# APM32M35XX register map
File version: 1.0
Registers are 32-bit, read-write, reset 0x0 unless marked. A register's access mark holds for its fields unless they carry their own. Offsets are from the block's base; [hi:lo] are bit positions; {n}, {i} and the like mark numbered series.

## TMR1 — Advanced-timers
Base 0x40012C00
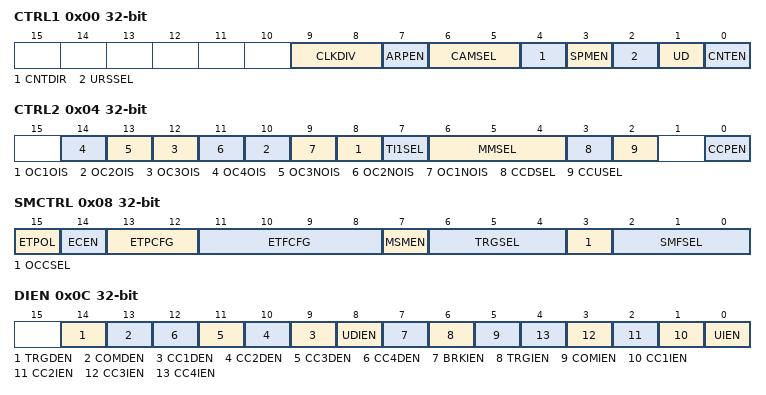
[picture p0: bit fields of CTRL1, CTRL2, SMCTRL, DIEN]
0x00 CTRL1 — control register 1
  [9:8] CLKDIV — Clock division
  [7] ARPEN — Auto-reload preload enable
  [6:5] CAMSEL — Center-aligned mode selection
  [4] CNTDIR — Direction
  [3] SPMEN — One-pulse mode
  [2] URSSEL — Update request source
  [1] UD — Update disable
  [0] CNTEN — Counter enable
0x04 CTRL2 — control register 2
  [2n+6] OC{n}OIS (n=1..4) — Output Idle state {n}
  [13] OC3NOIS — Output Idle state 3
  [11] OC2NOIS — Output Idle state 2
  [9] OC1NOIS — Output Idle state 1
  [7] TI1SEL — TI1 selection
  [6:4] MMSEL — Master mode selection
  [3] CCDSEL — Capture/compare DMA selection
  [2] CCUSEL — Capture/compare control update selection
  [0] CCPEN — Capture/compare preloaded control
0x08 SMCTRL — slave mode control register
  [15] ETPOL — External trigger polarity
  [14] ECEN — External clock enable
  [13:12] ETPCFG — External trigger prescaler
  [11:8] ETFCFG — External trigger filter
  [7] MSMEN — Master/Slave mode
  [6:4] TRGSEL — Trigger selection
  [3] OCCSEL — OCREF clear selection
  [2:0] SMFSEL — Slave mode selection
0x0C DIEN — DMA/Interrupt enable register
  [14] TRGDEN — Trigger DMA request enable
  [13] COMDEN — Reserved
  [n+8] CC{n}DEN (n=1..4) — Capture/Compare {n} DMA request enable
  [8] UDIEN — Update DMA request enable
  [7] BRKIEN — Break interrupt enable
  [6] TRGIEN — Trigger interrupt enable
  [5] COMIEN — COM interrupt enable
  [n] CC{n}IEN (n=1..4) — Capture/Compare {n} interrupt enable
  [0] UIEN — Update interrupt enable
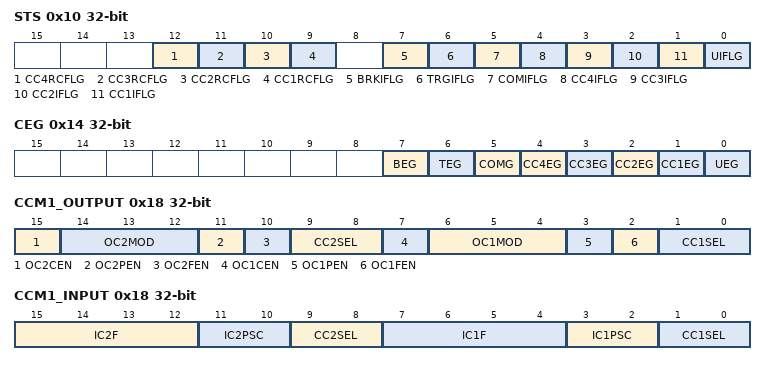
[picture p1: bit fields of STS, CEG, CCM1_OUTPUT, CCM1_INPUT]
0x10 STS — status register
  [12] CC4RCFLG — Capture/Compare 4 overcapture flag
  [11] CC3RCFLG — Capture/Compare 3 overcapture flag
  [10] CC2RCFLG — Capture/compare 2 overcapture flag
  [9] CC1RCFLG — Capture/Compare 1 overcapture flag
  [7] BRKIFLG — Break interrupt flag
  [6] TRGIFLG — Trigger interrupt flag
  [5] COMIFLG — COM interrupt flag
  [4] CC4IFLG — Capture/Compare 4 interrupt flag
  [3] CC3IFLG — Capture/Compare 3 interrupt flag
  [2] CC2IFLG — Capture/Compare 2 interrupt flag
  [1] CC1IFLG — Capture/compare 1 interrupt flag
  [0] UIFLG — Update interrupt flag
0x14 CEG wo — event generation register
  [7] BEG — Break generation
  [6] TEG — Trigger generation
  [5] COMG — Capture/Compare control update generation
  [n] CC{n}EG (n=1..4) — Capture/compare {n} generation
  [0] UEG — Update generation
0x18 CCM1_OUTPUT — capture/compare mode register (output mode)
  [15] OC2CEN — Output Compare 2 clear enable
  [14:12] OC2MOD — Output Compare 2 mode
  [11] OC2PEN — Output Compare 2 preload enable
  [10] OC2FEN — Output Compare 2 fast enable
  [9:8] CC2SEL — Capture/Compare 2 selection
  [7] OC1CEN — Output Compare 1 clear enable
  [6:4] OC1MOD — Output Compare 1 mode
  [3] OC1PEN — Output Compare 1 preload enable
  [2] OC1FEN — Output Compare 1 fast enable
  [1:0] CC1SEL — Capture/Compare 1 selection
0x18 CCM1_INPUT (alternate view of CCM1_OUTPUT) — capture/compare mode register 1 (input mode)
  [15:12] IC2F — Input capture 2 filter
  [11:10] IC2PSC — Input capture 2 prescaler
  [9:8] CC2SEL — Capture/Compare 2 selection
  [7:4] IC1F — Input capture 1 filter
  [3:2] IC1PSC — Input capture 1 prescaler
  [1:0] CC1SEL — Capture/Compare 1 selection
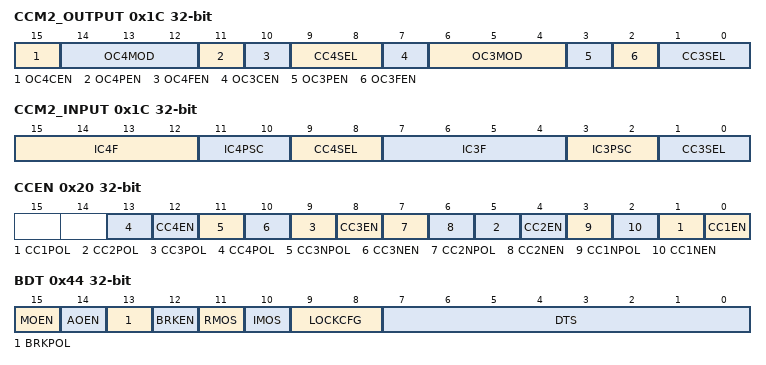
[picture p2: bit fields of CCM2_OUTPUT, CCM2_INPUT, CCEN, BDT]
0x1C CCM2_OUTPUT — capture/compare mode register (output mode)
  [15] OC4CEN — Output compare 4 clear enable
  [14:12] OC4MOD — Output compare 4 mode
  [11] OC4PEN — Output compare 4 preload enable
  [10] OC4FEN — Output compare 4 fast enable
  [9:8] CC4SEL — Capture/Compare 4 selection
  [7] OC3CEN — Output compare 3 clear enable
  [6:4] OC3MOD — Output compare 3 mode
  [3] OC3PEN — Output compare 3 preload enable
  [2] OC3FEN — Output compare 3 fast enable
  [1:0] CC3SEL — Capture/Compare 3 selection
0x1C CCM2_INPUT (alternate view of CCM2_OUTPUT) — capture/compare mode register 2 (input mode)
  [15:12] IC4F — Input capture 4 filter
  [11:10] IC4PSC — Input capture 4 prescaler
  [9:8] CC4SEL — Capture/Compare 4 selection
  [7:4] IC3F — Input capture 3 filter
  [3:2] IC3PSC — Input capture 3 prescaler
  [1:0] CC3SEL — Capture/compare 3 selection
0x20 CCEN — capture/compare enable register
  [4n-3] CC{n}POL (n=1..4) — Capture/Compare {n} output Polarity
  [4n-4] CC{n}EN (n=1..4) — Capture/Compare {n} output enable
  [11] CC3NPOL — Capture/Compare 3 output Polarity
  [10] CC3NEN — Capture/Compare 3 complementary output enable
  [7] CC2NPOL — Capture/Compare 2 output Polarity
  [6] CC2NEN — Capture/Compare 2 complementary output enable
  [3] CC1NPOL — Capture/Compare 1 output Polarity
  [2] CC1NEN — Capture/Compare 1 complementary output enable
0x24 CNT — counter
  [15:0] CNT — counter value
0x28 PSC — prescaler
  [15:0] PSC — Prescaler value
0x2C AUTORLD reset 0xFFFF — auto-reload register
  [15:0] AUTORLD — Auto-reload value
0x30 REPCNT — repetition counter register
  [7:0] REPCNT — Repetition counter value
{0x30+4i} CC{i} (i=1..3) — capture/compare register {i}
  [15:0] CC{i} — Capture/Compare {i} value
0x40 CC4 — capture/compare register 4
  [15:0] CC4 — Capture/Compare 3 value
0x44 BDT — break and dead-time register
  [15] MOEN — Main output enable
  [14] AOEN — Automatic output enable
  [13] BRKPOL — Break polarity
  [12] BRKEN — Break enable
  [11] RMOS — Off-state selection for Run mode
  [10] IMOS — Off-state selection for Idle mode
  [9:8] LOCKCFG — Lock configuration
  [7:0] DTS — Dead-time generator setup
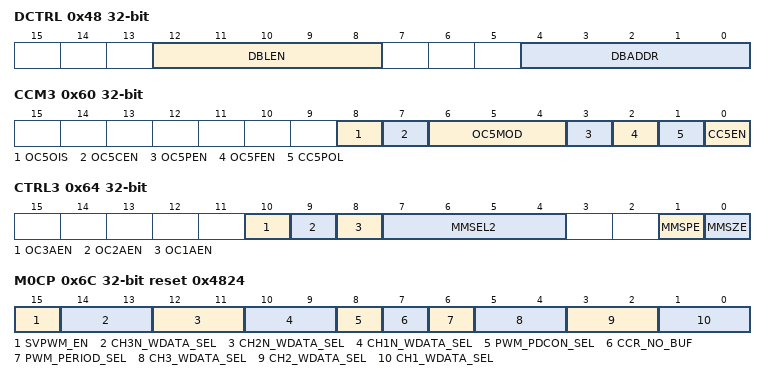
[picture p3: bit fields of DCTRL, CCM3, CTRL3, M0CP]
0x48 DCTRL — DMA control register
  [12:8] DBLEN — DMA burst length
  [4:0] DBADDR — DMA base address
0x4C DMADDR — DMA address for full transfer
  [15:0] DMADDR — DMA register for burst accesses
{0x4C+4i} CC{i}C (i=1..3) — capture/compare register complementary register {i}
  [15:0] CC{i}C — Channel {i} capture/compare register complementary register
0x5C CC5 — capture/compare register 5
  [15:0] CC5 — Capture/compare channel 5 value
0x60 CCM3 — capture/compare mode register (output mode)
  [8] OC5OIS — OC5 output idel state configure
  [7] OC5CEN — Output compare 5 clear enable
  [6:4] OC5MOD — Output compare 5 mode configure
  [3] OC5PEN — Output compare 5 preload enable
  [2] OC5FEN — Output compare 5 fast enable
  [1] CC5POL — Output compare 5 output polarity configure
  [0] CC5EN — Output compare 5 enable
0x64 CTRL3 — control register 3
  [10] OC3AEN — Output compare 3 asynchronous mode configure
  [9] OC2AEN — Output compare 2 asynchronous mode configure
  [8] OC1AEN — Output compare 1 asynchronous mode configure
  [7:4] MMSEL2 — Master mode signal select
  [1] MMSPE — TRGO when counter matches the autoreload register
  [0] MMSZE — TRGO when the counter returns to 0
0x68 BKFT — brake filter register
  [3:0] BKF — External brake input filter
0x6C M0CP reset 0x4824
  [15] SVPWM_EN — SVPWM function enable
  [14:13] CH3N_WDATA_SEL — Channel 3N data selection
  [12:11] CH2N_WDATA_SEL — Channel 2N data selection
  [10:9] CH1N_WDATA_SEL — Channel 1N data selection
  [8] PWM_PDCON_SEL — PDCON select
  [7] CCR_NO_BUF — CCR buffer enable
  [6] PWM_PERIOD_SEL — PWM cycle selection
  [5:4] CH3_WDATA_SEL — Channel 3 data selection
  [3:2] CH2_WDATA_SEL — Channel 2 data selection
  [1:0] CH1_WDATA_SEL — Channel 1 data selection
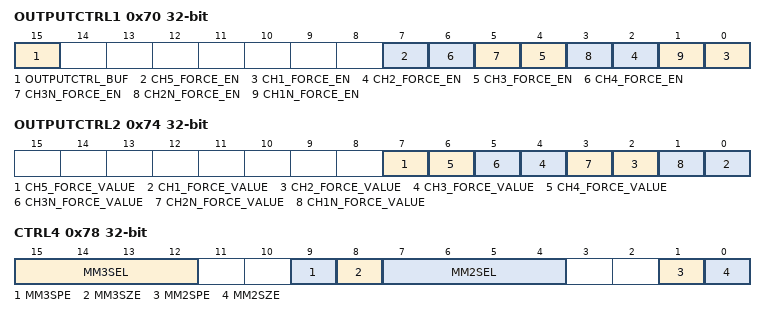
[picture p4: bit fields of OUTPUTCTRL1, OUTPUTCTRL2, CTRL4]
0x70 OUTPUTCTRL1 — output control register 1
  [15] OUTPUTCTRL_BUF — Output control buffering enable
  [7] CH5_FORCE_EN — Channel 5 outputs the control enable
  [2n-2] CH{n}_FORCE_EN (n=1..4) — Channel {n} outputs the control enable
  [5] CH3N_FORCE_EN — Complementary channel outputs the control enable for channel 3
  [3] CH2N_FORCE_EN — Complementary channel outputs the control enable for channel 2
  [1] CH1N_FORCE_EN — Complementary channel outputs the control enable for channel 1
0x74 OUTPUTCTRL2 — output control register 2
  [7] CH5_FORCE_VALUE — Channel 5 output level
  [2n-2] CH{n}_FORCE_VALUE (n=1..4) — Channel {n} output level
  [5] CH3N_FORCE_VALUE — Complementary channel output level for channel 3
  [3] CH2N_FORCE_VALUE — Complementary channel output level for channel 2
  [1] CH1N_FORCE_VALUE — Complementary channel output level for channel 1
0x78 CTRL4 — control register 4
  [15:12] MM3SEL — Master mode signal select
  [9] MM3SPE — TRGO3 when counter matches the autoreload register
  [8] MM3SZE — TRGO3 when the counter returns to 0
  [7:4] MM2SEL — Master mode signal select
  [1] MM2SPE — TRGO2 when counter matches the autoreload register
  [0] MM2SZE — TRGO2 when the counter returns to 0

## TMR2 — General-purpose-timers
Base 0x40000000
Same registers: TMR3 0x40000400, TMR4 0x40002000
Registers as TMR1, without REPCNT, BDT, CC{n}C (n=1..3), CC5, CCM3, CTRL3, BKFT, M0CP, OUTPUTCTRL1, OUTPUTCTRL2, CTRL4; these are added or differ:
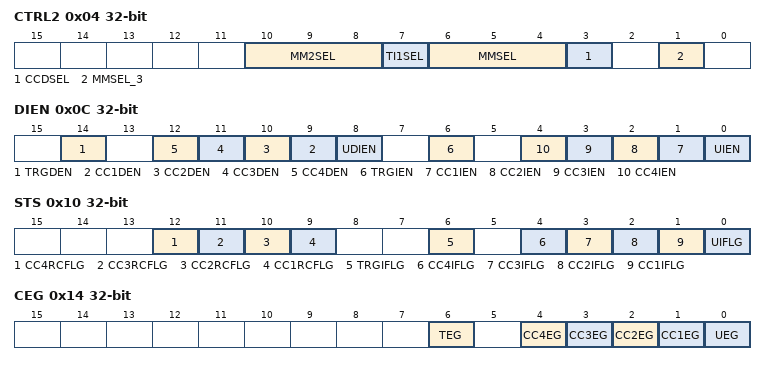
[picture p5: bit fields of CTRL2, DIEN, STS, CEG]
0x04 CTRL2 — control register 2
  [10:8] MM2SEL — Master Mode 2 Signal Select
  [7] TI1SEL — TI1 selection
  [6:4] MMSEL — Master mode selection
  [3] CCDSEL — Capture/compare DMA selection
  [1] MMSEL_3 — Supplementary signal of MMSEL
0x0C DIEN — DMA/Interrupt enable register
  [14] TRGDEN — Trigger DMA request enable
  [n+8] CC{n}DEN (n=1..4) — Capture/Compare {n} DMA request enable
  [8] UDIEN — Update DMA request enable
  [6] TRGIEN — Trigger interrupt enable
  [n] CC{n}IEN (n=1..4) — Capture/Compare {n} interrupt enable
  [0] UIEN — Update interrupt enable
0x10 STS — status register
  [12] CC4RCFLG — Capture/Compare 4 overcapture flag
  [11] CC3RCFLG — Capture/Compare 3 overcapture flag
  [10] CC2RCFLG — Capture/compare 2 overcapture flag
  [9] CC1RCFLG — Capture/Compare 1 overcapture flag
  [6] TRGIFLG — Trigger interrupt flag
  [4] CC4IFLG — Capture/Compare 4 interrupt flag
  [3] CC3IFLG — Capture/Compare 3 interrupt flag
  [2] CC2IFLG — Capture/Compare 2 interrupt flag
  [1] CC1IFLG — Capture/compare 1 interrupt flag
  [0] UIFLG — Update interrupt flag
0x14 CEG wo — event generation register
  [6] TEG — Trigger generation
  [n] CC{n}EG (n=1..4) — Capture/compare {n} generation
  [0] UEG — Update generation
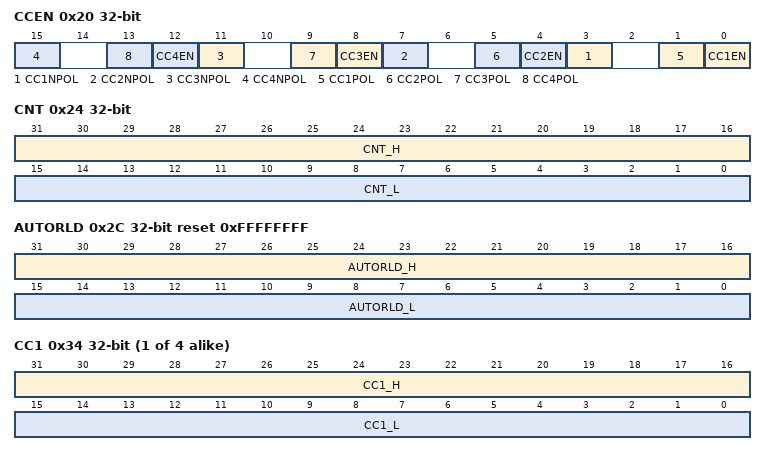
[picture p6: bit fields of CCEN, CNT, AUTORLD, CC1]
0x20 CCEN — capture/compare enable register
  [4n-1] CC{n}NPOL (n=1..4) — Capture/Compare {n} output Polarity
  [4n-3] CC{n}POL (n=1..4) — Capture/Compare {n} output Polarity
  [4n-4] CC{n}EN (n=1..4) — Capture/Compare {n} output enable
0x24 CNT — counter
  [31:16] CNT_H — Hige counter value(Only TMR2)
  [15:0] CNT_L — Low counter value
0x2C AUTORLD reset 0xFFFFFFFF — auto-reload register
  [31:16] AUTORLD_H — Hige Auto-reload value(Only TMR2)
  [15:0] AUTORLD_L — Low Auto-reload value
{0x30+4i} CC{i} (i=1..4) — capture/compare register {i}
  [31:16] CC1_H — Hige Capture/Compare 1 value(Only TMR2)
  [15:0] CC1_L — Low Capture/Compare 1 value
